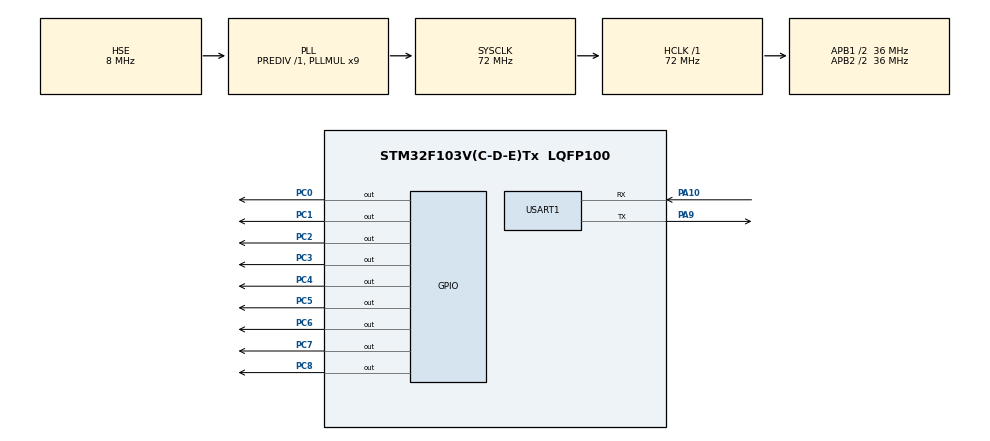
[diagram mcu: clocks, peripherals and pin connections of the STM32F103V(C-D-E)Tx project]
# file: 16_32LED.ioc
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Mcu.Family=STM32F1
Mcu.Name=STM32F103V(C-D-E)Tx
Mcu.Package=LQFP100
NVIC.PriorityGroup=NVIC_PRIORITYGROUP_4
OSC_IN.Mode=HSE-External-Clock-Source
OSC_IN.Signal=RCC_OSC_IN
OSC_OUT.Mode=HSE-External-Clock-Source
OSC_OUT.Signal=RCC_OSC_OUT
PA10.Mode=Asynchronous
PA10.Signal=USART1_RX
PA13.Mode=Serial_Wire
PA13.Signal=SYS_JTMS-SWDIO
PA14.Mode=Serial_Wire
PA14.Signal=SYS_JTCK-SWCLK
PA9.Mode=Asynchronous
PA9.Signal=USART1_TX
PC0.Signal=GPIO_Output
PC1.Signal=GPIO_Output
PC2.Signal=GPIO_Output
PC3.Signal=GPIO_Output
PC4.Signal=GPIO_Output
PC5.Signal=GPIO_Output
PC6.Signal=GPIO_Output
PC7.Signal=GPIO_Output
PC8.Signal=GPIO_Output
ProjectManager.HeapSize=0x200
ProjectManager.StackSize=0x400
ProjectManager.TargetToolchain=MDK-ARM V5
RCC.AHBFreq_Value=72000000
RCC.APB1CLKDivider=RCC_HCLK_DIV2
RCC.APB1Freq_Value=36000000
RCC.APB1TimFreq_Value=72000000
RCC.APB2CLKDivider=RCC_HCLK_DIV2
RCC.APB2Freq_Value=36000000
RCC.APB2TimFreq_Value=72000000
RCC.HCLKFreq_Value=72000000
RCC.PLLMUL=RCC_PLL_MUL9
RCC.PLLSourceVirtual=RCC_PLLSOURCE_HSE
RCC.SYSCLKFreq_VALUE=72000000
RCC.SYSCLKSource=RCC_SYSCLKSOURCE_PLLCLK
RCC.USBFreq_Value=72000000
USART1.VirtualMode=VM_ASYNC
board=custom

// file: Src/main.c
/* USER CODE BEGIN Header */
/**
  ******************************************************************************
  * @file           : main.c
  * @brief          : Main program body
  ******************************************************************************
  * @attention
  *
  * <h2><center>&copy; Copyright (c) 2019 STMicroelectronics.
  * All rights reserved.</center></h2>
  *
  * This software component is licensed by ST under BSD 3-Clause license,
  * the "License"; You may not use this file except in compliance with the
  * License. You may obtain a copy of the License at:
  *                        opensource.org/licenses/BSD-3-Clause
  *
  ******************************************************************************
  */
/* USER CODE END Header */

#include "main.h"

/* USER CODE BEGIN Includes */
#include "sdk_hc595.h"
#include "sdk_74LS138.h"
/* USER CODE END Includes */

/* USER CODE BEGIN PTD */
uint32_t val = 0xFFFF;
/* USER CODE END PTD */

UART_HandleTypeDef huart1;

void SystemClock_Config(void);
static void MX_GPIO_Init(void);
static void MX_USART1_UART_Init(void);

int main(void)
{

  /* MCU Configuration--------------------------------------------------------*/

  /* Reset of all peripherals, Initializes the Flash interface and the Systick. */
  HAL_Init();

  /* Configure the system clock */
  SystemClock_Config();

  /* Initialize all configured peripherals */
  MX_GPIO_Init();
  MX_USART1_UART_Init();
  /* USER CODE BEGIN 2 */

  ExtHC595_Send(val);
  MY_138_EN(1);
  /* USER CODE END 2 */

  /* Infinite loop */
  while (1)
  {

  }
}

void SystemClock_Config(void)
{
  RCC_OscInitTypeDef RCC_OscInitStruct = {0};
  RCC_ClkInitTypeDef RCC_ClkInitStruct = {0};

  /** Initializes the CPU, AHB and APB busses clocks
  */
  RCC_OscInitStruct.OscillatorType = RCC_OSCILLATORTYPE_HSE;
  RCC_OscInitStruct.HSEState = RCC_HSE_BYPASS;
  RCC_OscInitStruct.HSEPredivValue = RCC_HSE_PREDIV_DIV1;
  RCC_OscInitStruct.HSIState = RCC_HSI_ON;
  RCC_OscInitStruct.PLL.PLLState = RCC_PLL_ON;
  RCC_OscInitStruct.PLL.PLLSource = RCC_PLLSOURCE_HSE;
  RCC_OscInitStruct.PLL.PLLMUL = RCC_PLL_MUL9;
  if (HAL_RCC_OscConfig(&RCC_OscInitStruct) != HAL_OK)
  {
    Error_Handler();
  }
  /** Initializes the CPU, AHB and APB busses clocks
  */
  RCC_ClkInitStruct.ClockType = RCC_CLOCKTYPE_HCLK|RCC_CLOCKTYPE_SYSCLK
                              |RCC_CLOCKTYPE_PCLK1|RCC_CLOCKTYPE_PCLK2;
  RCC_ClkInitStruct.SYSCLKSource = RCC_SYSCLKSOURCE_PLLCLK;
  RCC_ClkInitStruct.AHBCLKDivider = RCC_SYSCLK_DIV1;
  RCC_ClkInitStruct.APB1CLKDivider = RCC_HCLK_DIV2;
  RCC_ClkInitStruct.APB2CLKDivider = RCC_HCLK_DIV2;

  if (HAL_RCC_ClockConfig(&RCC_ClkInitStruct, FLASH_LATENCY_2) != HAL_OK)
  {
    Error_Handler();
  }
}

static void MX_USART1_UART_Init(void)
{

  huart1.Instance = USART1;
  huart1.Init.BaudRate = 115200;
  huart1.Init.WordLength = UART_WORDLENGTH_8B;
  huart1.Init.StopBits = UART_STOPBITS_1;
  huart1.Init.Parity = UART_PARITY_NONE;
  huart1.Init.Mode = UART_MODE_TX_RX;
  huart1.Init.HwFlowCtl = UART_HWCONTROL_NONE;
  huart1.Init.OverSampling = UART_OVERSAMPLING_16;
  if (HAL_UART_Init(&huart1) != HAL_OK)
  {
    Error_Handler();
  }

}

static void MX_GPIO_Init(void)
{
  GPIO_InitTypeDef GPIO_InitStruct = {0};

  /* GPIO Ports Clock Enable */
  __HAL_RCC_GPIOC_CLK_ENABLE();
  __HAL_RCC_GPIOA_CLK_ENABLE();

  /*Configure GPIO pin Output Level */
  HAL_GPIO_WritePin(GPIOC, GPIO_PIN_0|GPIO_PIN_1|GPIO_PIN_2|GPIO_PIN_3
                          |GPIO_PIN_4|GPIO_PIN_5|GPIO_PIN_6|GPIO_PIN_7
                          |GPIO_PIN_8, GPIO_PIN_RESET);

  /*Configure GPIO pins : PC0 PC1 PC2 PC3
                           PC4 PC5 PC6 PC7
                           PC8 */
  GPIO_InitStruct.Pin = GPIO_PIN_0|GPIO_PIN_1|GPIO_PIN_2|GPIO_PIN_3
                          |GPIO_PIN_4|GPIO_PIN_5|GPIO_PIN_6|GPIO_PIN_7
                          |GPIO_PIN_8;
  GPIO_InitStruct.Mode = GPIO_MODE_OUTPUT_PP;
  GPIO_InitStruct.Pull = GPIO_NOPULL;
  GPIO_InitStruct.Speed = GPIO_SPEED_FREQ_LOW;
  HAL_GPIO_Init(GPIOC, &GPIO_InitStruct);

}

void Error_Handler(void)
{
}

/************************ (C) COPYRIGHT STMicroelectronics *****END OF FILE****/
